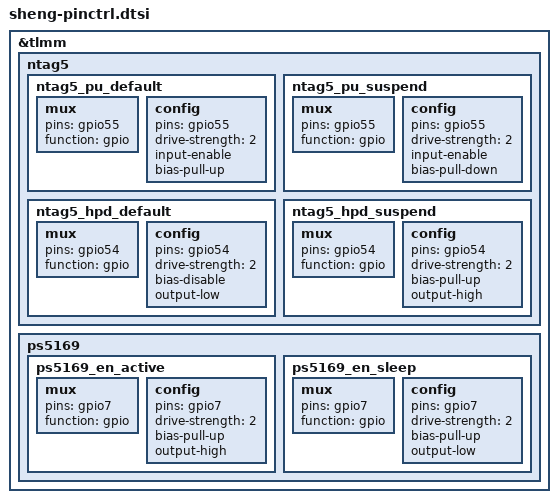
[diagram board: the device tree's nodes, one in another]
/*for sheng pinctrl */
&tlmm {
	ntag5 {
			ntag5_pu_default: ntag5_pu_default {
					mux {
						pins = "gpio55";
						function = "gpio";
					};

					config {
						pins = "gpio55";
						drive-strength = <2>; /* 2 MA */
						input-enable;
						/* 拉高方式恢复 */
						bias-pull-up;
					};
			};

			ntag5_pu_suspend: ntag5_pu_suspend {
					mux {
						pins = "gpio55";
						function = "gpio";
					};

					config {
						pins = "gpio55";
						drive-strength = <2>; /* 2 MA */
						input-enable;
						/* 拉低方式触发 */
						bias-pull-down;
					};
			};

			ntag5_hpd_default: ntag5_hpd_default {
					mux {
						pins = "gpio54";
						function = "gpio";
					};

					config {
						pins = "gpio54";
						drive-strength = <2>; /* 2 MA */
						// 默认态 bias-disable是悬空
						bias-disable;
						output-low;
					};
			};

			ntag5_hpd_suspend: ntag5_hpd_suspend {
					mux {
						pins = "gpio54";
						function = "gpio";
					};

					config {
						pins = "gpio54";
						drive-strength = <2>; /* 2 MA */
						/* 拉高方式触发 */
						bias-pull-up;
						output-high;
					};
			};
	};

	ps5169 {
		ps5169_en_active: ps5169_en_active {
			mux {
				pins = "gpio7";
				function = "gpio";
			};
			config {
				pins = "gpio7";
				drive-strength = <2>;
				bias-pull-up;
				output-high;
			};
		};
		ps5169_en_sleep: ps5169_en_sleep {
			mux {
				pins = "gpio7";
				function = "gpio";
			};
			config {
				pins = "gpio7";
				drive-strength = <2>;
				bias-pull-up;
				output-low;
			};
		};
	};
};
